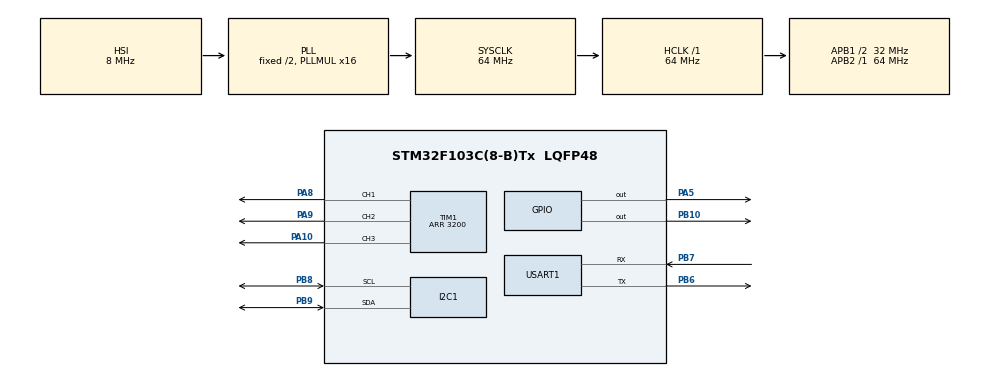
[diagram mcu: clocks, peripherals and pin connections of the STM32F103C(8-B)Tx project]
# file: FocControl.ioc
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ARM.CMSIS-DSP.1.17.0.CMSISJjDSP=Source
I2C1.DualAddressMode=I2C_DUALADDRESS_DISABLE
I2C1.I2C_Mode=I2C_Standard
I2C1.NoStretchMode=I2C_NOSTRETCH_DISABLE
Mcu.Family=STM32F1
Mcu.Name=STM32F103C(8-B)Tx
Mcu.Package=LQFP48
NVIC.PriorityGroup=NVIC_PRIORITYGROUP_4
PA10.Signal=S_TIM1_CH3
PA13.Mode=Serial_Wire
PA13.Signal=SYS_JTMS-SWDIO
PA14.Mode=Serial_Wire
PA14.Signal=SYS_JTCK-SWCLK
PA5.GPIO_PuPd=GPIO_PULLUP
PA5.Signal=GPIO_Output
PA8.Signal=S_TIM1_CH1
PA9.Signal=S_TIM1_CH2
PB10.GPIO_PuPd=GPIO_PULLUP
PB10.PinState=GPIO_PIN_SET
PB10.Signal=GPIO_Output
PB6.Mode=Asynchronous
PB6.Signal=USART1_TX
PB7.Mode=Asynchronous
PB7.Signal=USART1_RX
PB8.Mode=I2C
PB8.Signal=I2C1_SCL
PB9.Mode=I2C
PB9.Signal=I2C1_SDA
PD0-OSC_IN.Mode=HSE-External-Oscillator
PD0-OSC_IN.Signal=RCC_OSC_IN
PD1-OSC_OUT.Mode=HSE-External-Oscillator
PD1-OSC_OUT.Signal=RCC_OSC_OUT
ProjectManager.HeapSize=0x200
ProjectManager.StackSize=0x400
ProjectManager.TargetToolchain=MDK-ARM V5.32
RCC.AHBFreq_Value=64000000
RCC.APB1CLKDivider=RCC_HCLK_DIV2
RCC.APB1Freq_Value=32000000
RCC.APB1TimFreq_Value=64000000
RCC.APB2Freq_Value=64000000
RCC.APB2TimFreq_Value=64000000
RCC.HCLKFreq_Value=64000000
RCC.PLLMUL=RCC_PLL_MUL16
RCC.SYSCLKFreq_VALUE=64000000
RCC.SYSCLKSource=RCC_SYSCLKSOURCE_PLLCLK
RCC.USBFreq_Value=64000000
SH.S_TIM1_CH1.0=TIM1_CH1,PWM Generation1 CH1
SH.S_TIM1_CH2.0=TIM1_CH2,PWM Generation2 CH2
SH.S_TIM1_CH3.0=TIM1_CH3,PWM Generation3 CH3
TIM1.AutoReloadPreload=TIM_AUTORELOAD_PRELOAD_ENABLE
TIM1.Channel-PWM\ Generation1\ CH1=TIM_CHANNEL_1
TIM1.Channel-PWM\ Generation2\ CH2=TIM_CHANNEL_2
TIM1.Channel-PWM\ Generation3\ CH3=TIM_CHANNEL_3
TIM1.CounterMode=TIM_COUNTERMODE_CENTERALIGNED1
TIM1.Period=3200
TIM1.Pulse-PWM\ Generation1\ CH1=100
TIM1.Pulse-PWM\ Generation2\ CH2=400
TIM1.Pulse-PWM\ Generation3\ CH3=600
TIM2.Channel-Output\ Compare1\ No\ Output=TIM_CHANNEL_1
TIM2.Prescaler=64
USART1.VirtualMode=VM_ASYNC
VP_ARM.CMSIS-DSP_VS_CMSISJjDSP_1.17.0_1.17.0.Mode=CMSISJjDSP
VP_TIM1_VS_ClockSourceINT.Mode=Internal
VP_TIM2_VS_ClockSourceINT.Mode=Internal
VP_TIM2_VS_no_output1.Mode=Output Compare1 No Output
board=custom

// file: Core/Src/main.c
/* USER CODE BEGIN Header */
/**
  ******************************************************************************
  * @file           : main.c
  * @brief          : Main program body
  ******************************************************************************
  * @attention
  *
  * Copyright (c) 2026 STMicroelectronics.
  * All rights reserved.
  *
  * This software is licensed under terms that can be found in the LICENSE file
  * in the root directory of this software component.
  * If no LICENSE file comes with this software, it is provided AS-IS.
  *
  ******************************************************************************
  */
/* USER CODE END Header */
#include "main.h"
#include "i2c.h"
#include "tim.h"
#include "usart.h"
#include "gpio.h"

/* USER CODE BEGIN Includes */
#include "freemaster.h"
#include "tms.h"
/* USER CODE END Includes */

void SystemClock_Config(void);

int main(void)
{

  /* MCU Configuration--------------------------------------------------------*/

  /* Reset of all peripherals, Initializes the Flash interface and the Systick. */
  HAL_Init();

  /* Configure the system clock */
  SystemClock_Config();

  /* Initialize all configured peripherals */
  MX_GPIO_Init();
  MX_USART1_UART_Init();
  MX_I2C1_Init();
  MX_TIM1_Init();
  MX_TIM2_Init();
  /* USER CODE BEGIN 2 */

    /*初始化*/
    Tms_If_Init();
  /* USER CODE END 2 */

  /* Infinite loop */
  while (1)
  {

    /* USER CODE BEGIN 3 */
    /*任务轮询*/
    Tms_If_Poll();

  }
  /* USER CODE END 3 */
}

void SystemClock_Config(void)
{
  RCC_OscInitTypeDef RCC_OscInitStruct = {0};
  RCC_ClkInitTypeDef RCC_ClkInitStruct = {0};

  /** Initializes the RCC Oscillators according to the specified parameters
  * in the RCC_OscInitTypeDef structure.
  */
  RCC_OscInitStruct.OscillatorType = RCC_OSCILLATORTYPE_HSI;
  RCC_OscInitStruct.HSIState = RCC_HSI_ON;
  RCC_OscInitStruct.HSICalibrationValue = RCC_HSICALIBRATION_DEFAULT;
  RCC_OscInitStruct.PLL.PLLState = RCC_PLL_ON;
  RCC_OscInitStruct.PLL.PLLSource = RCC_PLLSOURCE_HSI_DIV2;
  RCC_OscInitStruct.PLL.PLLMUL = RCC_PLL_MUL16;
  if (HAL_RCC_OscConfig(&RCC_OscInitStruct) != HAL_OK)
  {
    Error_Handler();
  }

  /** Initializes the CPU, AHB and APB buses clocks
  */
  RCC_ClkInitStruct.ClockType = RCC_CLOCKTYPE_HCLK|RCC_CLOCKTYPE_SYSCLK
                              |RCC_CLOCKTYPE_PCLK1|RCC_CLOCKTYPE_PCLK2;
  RCC_ClkInitStruct.SYSCLKSource = RCC_SYSCLKSOURCE_PLLCLK;
  RCC_ClkInitStruct.AHBCLKDivider = RCC_SYSCLK_DIV1;
  RCC_ClkInitStruct.APB1CLKDivider = RCC_HCLK_DIV2;
  RCC_ClkInitStruct.APB2CLKDivider = RCC_HCLK_DIV1;

  if (HAL_RCC_ClockConfig(&RCC_ClkInitStruct, FLASH_LATENCY_2) != HAL_OK)
  {
    Error_Handler();
  }
}

void Error_Handler(void)
{
  __disable_irq();
  while (1)
  {
  }
}
